# f29h85x_cpu2_ipc_rcv_regs register map
Vendor: Texas Instruments
Peripheral module from a debugger description file (folder C29).
Registers are 32-bit, read-only, no defined reset value unless marked. A register's access mark holds for its fields unless they carry their own. Offsets are as the file gives them; lines under a group give offsets from that group; [hi:lo] are bit positions; {n}, {i} and the like mark numbered series; 'fields as' and 'values as' point back to an identical list; <NAME> marks a mode.

## CPU2_IPC_RCV_REGS — CPU2 IPC RCV Registers
{0x0+0x800*i} CPU2_IPC_RCV_REGS_RegisterFile0[{i}] (i=0..3) group
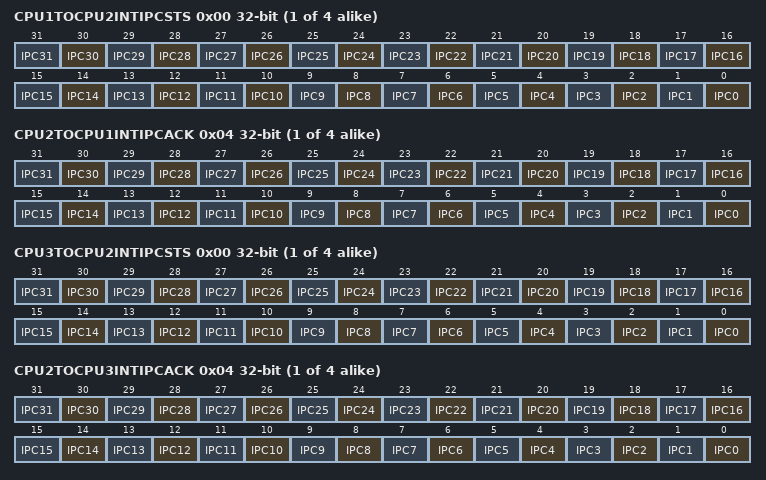
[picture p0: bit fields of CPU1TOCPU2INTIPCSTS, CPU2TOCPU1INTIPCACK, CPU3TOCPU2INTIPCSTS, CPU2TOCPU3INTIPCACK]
  0x00 CPU1TOCPU2INTIPCSTS
    [n] IPC{n} (n=0..31) — Local IPC Flag {n} Status
  0x04 CPU2TOCPU1INTIPCACK rw
    [n] IPC{n} (n=0..31) — Acknowledgement from CPU1 to CPU2TOCPU1IPCFLG.IPC{n} bit
  0x10 CPU1TOCPU2INTIPCRECVCOM
    [31:0] COMMAND — Refelects the state of CPU1TOCPU2INT IPCRECVCOM register
  0x14 CPU1TOCPU2INTIPCRECVADDR
    [31:0] ADDRESS — Refelects the state of CPU1TOCPU2INT IPCRECVADDR register
  0x18 CPU1TOCPU2INTIPCRECVDATA
    [31:0] DATA — Refelects the state of CPU1TOCPU2INT IPCRECVDATA register
  0x1C CPU2TOCPU1INTLOCALREPLY rw
    [31:0] REPLY — CPU2 to CPU1 IPC Reply
{0x2000+0x800*i} CPU2_IPC_RCV_REGS_RegisterFile1[{i}] (i=0..3) group
  0x00 CPU3TOCPU2INTIPCSTS
    [n] IPC{n} (n=0..31) — Local IPC Flag {n} Status
  0x04 CPU2TOCPU3INTIPCACK rw
    [n] IPC{n} (n=0..31) — Acknowledgement from CPU3 to CPU2TOCPU3IPCFLG.IPC{n} bit
  0x10 CPU3TOCPU2INTIPCRECVCOM
    [31:0] COMMAND — Refelects the state of CPU3TOCPU2INT IPCRECVCOM register
  0x14 CPU3TOCPU2INTIPCRECVADDR
    [31:0] ADDRESS — Refelects the state of CPU3TOCPU2INT IPCRECVADDR register
  0x18 CPU3TOCPU2INTIPCRECVDATA
    [31:0] DATA — Refelects the state of CPU3TOCPU2INT IPCRECVDATA register
  0x1C CPU2TOCPU3INTLOCALREPLY rw
    [31:0] REPLY — CPU2 to CPU3 IPC Reply
{0x6000+0x1000*i} CPU2_IPC_RCV_REGS_RegisterFile2[{i}] (i=0..1) group
